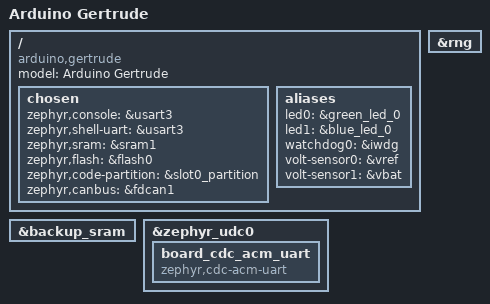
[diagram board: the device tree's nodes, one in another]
/*
 * Copyright (c) 2021 Linaro Limited
 * Copyright (c) 2023 Thomas Stranger
 *
 * SPDX-License-Identifier: Apache-2.0
 */

/dts-v1/;
#include "arduino_gertrude-common.dtsi"

/ {
	model = "Arduino Gertrude";
	compatible = "arduino,gertrude";

	#address-cells = <1>;
	#size-cells = <1>;

	chosen {
		zephyr,console = &usart3;
		zephyr,shell-uart = &usart3;
		zephyr,sram = &sram1;
		zephyr,flash = &flash0;
		zephyr,code-partition = &slot0_partition;
		zephyr,canbus = &fdcan1;
	};

	aliases {
		led0 = &green_led_0;
		led1 = &blue_led_0;
		watchdog0 = &iwdg;
		volt-sensor0 = &vref;
		volt-sensor1 = &vbat;
	};
};

&rng {
	status = "okay";
};

&backup_sram {
	status = "okay";
};

&zephyr_udc0 {
	board_cdc_acm_uart: board_cdc_acm_uart {
		compatible = "zephyr,cdc-acm-uart";
		status = "okay";
	};
};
